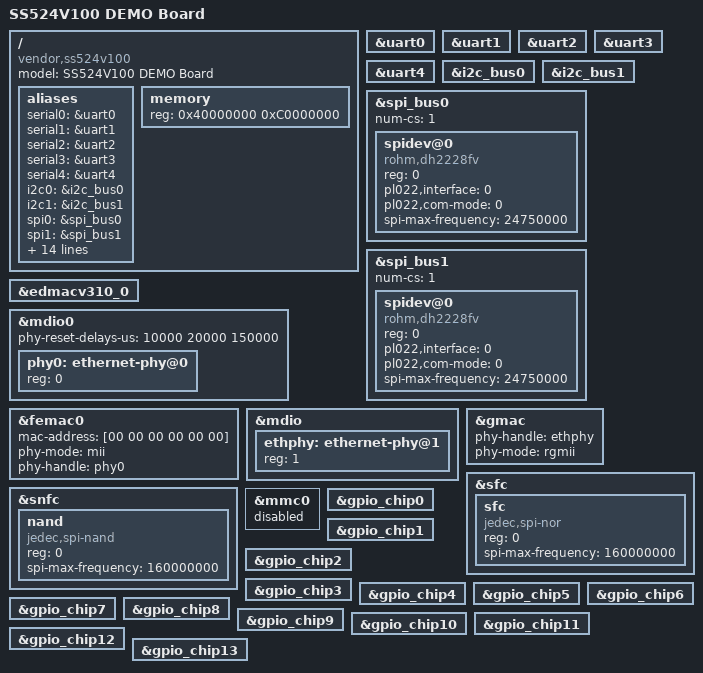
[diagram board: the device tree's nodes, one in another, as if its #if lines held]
/*
 * Copyright (c) 2013-2014 Linaro Ltd.
 * Copyright (c) 2015-2020 Shenshu Technologies Co., Ltd.
 *
 * This program is free software; you can redistribute  it and/or modify it
 * under  the terms of  the GNU General  Public License as published by the
 * Free Software Foundation;  either version 2 of the  License, or (at your
 * option) any later version.
 *
 * This program is distributed in the hope that it will be useful,
 * but WITHOUT ANY WARRANTY; without even the implied warranty of
 * MERCHANTABILITY or FITNESS FOR A PARTICULAR PURPOSE. See the
 * GNU General Public License for more details.
 *
 * You should have received a copy of the GNU General Public License
 * along with this program.  If not, see <http://www.gnu.org/licenses/>.
 *
 */

/dts-v1/;
#include "ss524v100.dtsi"

/ {
	model = "SS524V100 DEMO Board";
	compatible = "vendor,ss524v100";

	aliases {
		serial0 = &uart0;
		serial1 = &uart1;
		serial2 = &uart2;
		serial3 = &uart3;
		serial4 = &uart4;
		i2c0 = &i2c_bus0;
		i2c1 = &i2c_bus1;
		spi0 = &spi_bus0;
		spi1 = &spi_bus1;
		gpio0 = &gpio_chip0;
		gpio1 = &gpio_chip1;
		gpio2 = &gpio_chip2;
		gpio3 = &gpio_chip3;
		gpio4 = &gpio_chip4;
		gpio5 = &gpio_chip5;
		gpio6 = &gpio_chip6;
		gpio7 = &gpio_chip7;
		gpio8 = &gpio_chip8;
		gpio9 = &gpio_chip9;
		gpio10 = &gpio_chip10;
		gpio11 = &gpio_chip11;
		gpio12 = &gpio_chip12;
		gpio13 = &gpio_chip13;
	};

	memory {
		device_type = "memory";
		reg = <0x40000000 0xC0000000>;
	};
};

&uart0 {
	status = "okay";
};

&uart1 {
	status = "okay";
};

&uart2 {
	status = "okay";
};

&uart3 {
	status = "okay";
};

&uart4 {
	status = "okay";
};

&i2c_bus0 {
    status = "okay";
};

&i2c_bus1 {
    status = "okay";
};


&spi_bus0{
    status = "okay";
    num-cs = <1>;

    spidev@0 {
        compatible = "rohm,dh2228fv";
        reg = <0>;
        pl022,interface = <0>;
        pl022,com-mode = <0>;
        spi-max-frequency = <24750000>;
    };
};

&spi_bus1{
	status = "okay";
	num-cs = <1>;

	spidev@0 {
		compatible = "rohm,dh2228fv";
		reg = <0>;
		pl022,interface = <0>;
		pl022,com-mode = <0>;
		spi-max-frequency = <24750000>;
	};
};

&edmacv310_0 {
    status = "okay";
};

&mdio0 {
	phy-reset-delays-us = <10000 20000 150000>;
	phy0: ethernet-phy@0 {
		reg = <0>;
	};
};

&femac0 {
	mac-address = [00 00 00 00 00 00];
	phy-mode = "mii";
	phy-handle = <&phy0>;
	status = "okay";
};

&mdio {
	ethphy: ethernet-phy@1 {
		reg = <1>;
	};
};
&gmac {
	phy-handle = <&ethphy>;
	phy-mode = "rgmii";
};

&sfc {
	sfc {
		   compatible = "jedec,spi-nor";
		   reg = <0>;
		   spi-max-frequency = <160000000>;
	};
};

&snfc {
	nand {
		   compatible = "jedec,spi-nand";
		   reg = <0>;
		   spi-max-frequency = <160000000>;
	};
};

&mmc0 {
#ifdef CONFIG_MTD
	status = "disabled";
#else
	status = "okay";
#endif
};

&gpio_chip0 {
	status = "okay";
};

&gpio_chip1 {
	status = "okay";
};

&gpio_chip2 {
	status = "okay";
};

&gpio_chip3 {
	status = "okay";
};

&gpio_chip4 {
	status = "okay";
};

&gpio_chip5 {
	status = "okay";
};

&gpio_chip6 {
	status = "okay";
};

&gpio_chip7 {
	status = "okay";
};

&gpio_chip8 {
	status = "okay";
};

&gpio_chip9 {
	status = "okay";
};

&gpio_chip10 {
	status = "okay";
};

&gpio_chip11 {
	status = "okay";
};

&gpio_chip12 {
	status = "okay";
};

&gpio_chip13 {
	status = "okay";
};

